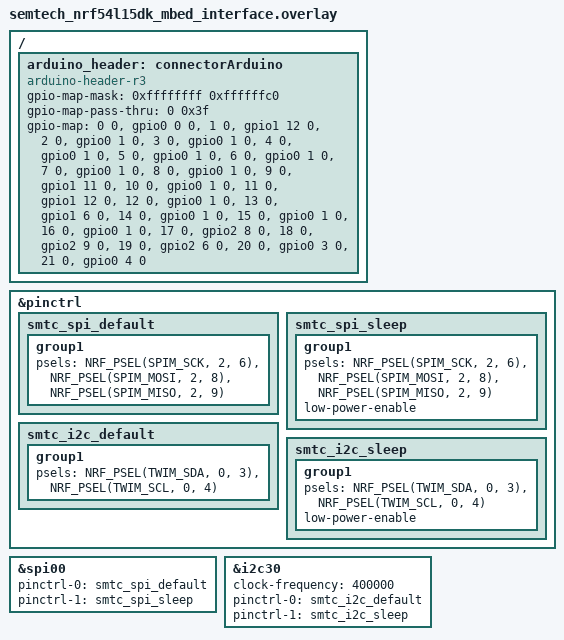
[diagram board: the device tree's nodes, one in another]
/*
 * Copyright (c) 2025 Semtech Corporation
 *
 * SPDX-License-Identifier: Apache-2.0
 */

/ {
    arduino_header: connectorArduino {
        compatible = "arduino-header-r3";
        #gpio-cells = <2>;
        gpio-map-mask = <0xffffffff 0xffffffc0>;
        gpio-map-pass-thru = <0 0x3f>;
        gpio-map = <0 0 &gpio0 0 0>, /* A0 */
                   <1 0 &gpio1 12 0>, /* A1 */
                   <2 0 &gpio0 1 0>, /* A2 is NC -> LED1 */
                   <3 0 &gpio0 1 0>, /* A3 is NC -> LED1 */
                   <4 0 &gpio0 1 0>, /* A4 is NC -> LED1 */
                   <5 0 &gpio0 1 0>, /* A5 is NC -> LED1 */
                   <6 0 &gpio0 1 0>, /* D0 is NC -> LED1 */
                   <7 0 &gpio0 1 0>, /* D1 is NC -> LED1 */
                   <8 0 &gpio0 1 0>, /* D2 is NC -> LED1 */
                   <9 0 &gpio1 11 0>, /* D3 */
                   <10 0 &gpio0 1 0>, /* D4 is NC -> LED1 */
                   <11 0 &gpio1 12 0>, /* D5 */
                   <12 0 &gpio0 1 0>, /* D6 is NC -> LED1 */
                   <13 0 &gpio1 6 0>, /* D7 */
                   <14 0 &gpio0 1 0>, /* D8 is NC -> LED1 */
                   <15 0 &gpio0 1 0>, /* D9 is NC -> LED1 */
                   <16 0 &gpio0 1 0>, /* D10 is NC -> LED1 */
                   <17 0 &gpio2 8 0>, /* D11 */
                   <18 0 &gpio2 9 0>, /* D12 */
                   <19 0 &gpio2 6 0>, /* D13 */
                   <20 0 &gpio0 3 0>,  /* D14 (SDA) */
                   <21 0 &gpio0 4 0>;  /* D15 (SCL) */
     };
};

// Redirect SPI pins (default don't use the same pins) and I2C pins
&pinctrl {

    //SPI
    smtc_spi_default: smtc_spi_default {
        group1 {
            psels = <NRF_PSEL(SPIM_SCK, 2, 6)>,
                    <NRF_PSEL(SPIM_MOSI, 2, 8)>,
                    <NRF_PSEL(SPIM_MISO, 2, 9)>;
        };
    };

    smtc_spi_sleep: smtc_spi_sleep {
         group1 {
              psels = <NRF_PSEL(SPIM_SCK, 2, 6)>,
                      <NRF_PSEL(SPIM_MOSI, 2, 8)>,
                      <NRF_PSEL(SPIM_MISO, 2, 9)>;
              low-power-enable;
         };
    };

    //I2C
    smtc_i2c_default: smtc_i2c_default {
         group1 {
              psels = <NRF_PSEL(TWIM_SDA, 0, 3)>,
                      <NRF_PSEL(TWIM_SCL, 0, 4)>;
         };
    };
    smtc_i2c_sleep: smtc_i2c_sleep {
         group1 {
              psels = <NRF_PSEL(TWIM_SDA, 0, 3)>,
                      <NRF_PSEL(TWIM_SCL, 0, 4)>;
              low-power-enable;
         };
    };
};

arduino_spi: &spi00 {
    status = "okay";
    pinctrl-0 = <&smtc_spi_default>;
    pinctrl-1 = <&smtc_spi_sleep>;
    pinctrl-names = "default", "sleep";
};

arduino_i2c: &i2c30 {
    status = "okay";
    clock-frequency = <400000>;
    pinctrl-0 = <&smtc_i2c_default>;
    pinctrl-1 = <&smtc_i2c_sleep>;
    pinctrl-names = "default", "sleep";
};
